# soc register map
Vendor: litex
Litex SoC 2022-08-25 21:57:28
Registers are 32-bit, read-write, reset 0x0 unless marked. A register's access mark holds for its fields unless they carry their own. Offsets are from the block's base; lines under a group give offsets from that group; [hi:lo] are bit positions; {n}, {i} and the like mark numbered series; 'fields as' and 'values as' point back to an identical list; <NAME> marks a mode.

## Memory map
0xF0000000 BPU size 0x24
0xF0000800 CTRL size 0xC
0xF0001000 DMATEST size 0x28
0xF0001800 IDENTIFIER_MEM size 0x4
0xF0002000 TIMER0 size 0x20
0xF0002800 TIMER1 size 0x20
0xF0003000 UART size 0x20

## Interrupts
0 uart (UART)
1 timer0 (TIMER0)
2 timer1 (TIMER1)
3 dmatest (DMATEST)

## Further device data
memoryRegions:
  ROM baseAddress=0x00000000 size=0x00020000
  SRAM baseAddress=0x10000000 size=0x00002000
  CSR baseAddress=0xF0000000 size=0x00010000
constants:
  CONFIG_CLOCK_FREQUENCY value=1000000
  CONFIG_CPU_HAS_INTERRUPT value=None
  CONFIG_CPU_RESET_ADDR value=0
  CONFIG_CPU_HAS_DCACHE value=None
  CONFIG_CPU_HAS_ICACHE value=None
  CONFIG_CPU_TYPE_VEXRISCV value=None
  CONFIG_CPU_VARIANT_STANDARD value=None
  CONFIG_CPU_HUMAN_NAME value=VexRiscv
  CONFIG_CPU_NOP value=nop
  CONFIG_CSR_DATA_WIDTH value=32
  CONFIG_CSR_ALIGNMENT value=32
  CONFIG_BUS_STANDARD value=WISHBONE
  CONFIG_BUS_DATA_WIDTH value=32
  CONFIG_BUS_ADDRESS_WIDTH value=32
  CONFIG_BUS_BURSTING value=0
  BPU_IDENTIFICATION value=2880249322
  DMATEST_INTERRUPT value=3
  TIMER0_INTERRUPT value=1
  TIMER1_INTERRUPT value=2
  UART_INTERRUPT value=0

## BPU
Base 0xF0000000
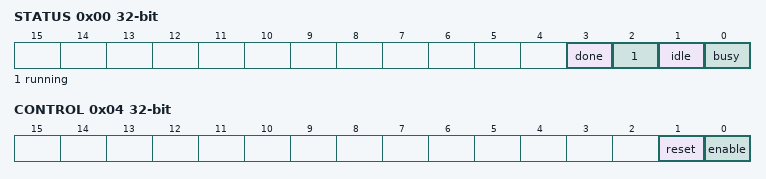
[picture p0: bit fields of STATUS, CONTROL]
0x00 STATUS — BPU Status
  [3] done — BPU Done
  [2] running — BPU Running
  [1] idle — BPU Idle
  [0] busy — BPU Busy
0x04 CONTROL
  [1] reset — Reset BPU
  [0] enable — Enable BPU
0x08 INSTRUCTION
0x0C SRC
0x10 DST
0x14 LENGTH
0x18 OFFSET
0x1C DATA
0x20 TICK

## CTRL
Base 0xF0000800
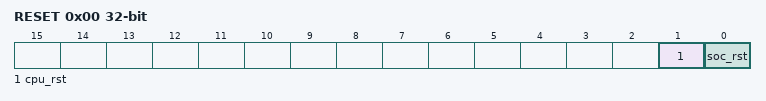
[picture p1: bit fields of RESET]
0x00 RESET
  [1] cpu_rst — Write `1` to this register to reset the CPU(s) of the SoC (Hold Reset)
  [0] soc_rst — Write `1` to this register to reset the full SoC (Pulse Reset)
0x04 SCRATCH reset 0x12345678 — Use this register as a scratch space to verify that software read/write accesses to the Wishbone/CSR bus are working correctly. The initial reset value of 0x1234578 can be used to verify endianness.
0x08 BUS_ERRORS — Total number of Wishbone bus errors (timeouts) since start.

## DMATEST
Base 0xF0001000
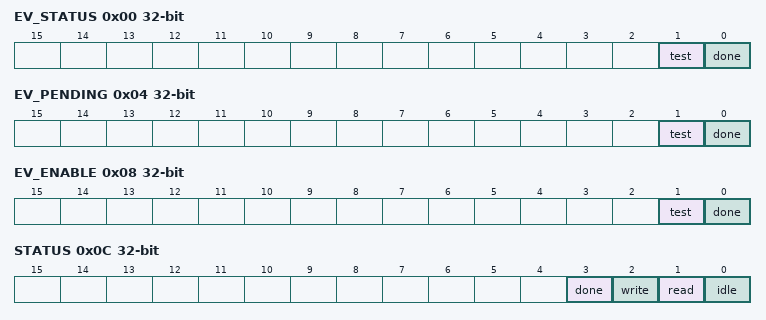
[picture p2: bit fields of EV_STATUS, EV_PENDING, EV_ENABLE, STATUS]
0x00 EV_STATUS — This register contains the current raw level of the test event trigger. Writes to this register have no effect.
  [1] test — Level of the ``test`` event
  [0] done — Level of the ``done`` event
0x04 EV_PENDING — When a test event occurs, the corresponding bit will be set in this register. To clear the Event, set the corresponding bit in this register.
  [1] test — `1` if a `test` event occurred. This Event is **level triggered** when the signal is **high**.
  [0] done — `1` if a `done` event occurred. This Event is triggered on a **falling** edge.
0x08 EV_ENABLE — This register enables the corresponding test events. Write a ``0`` to this register to disable individual events.
  [1] test — Write a ``1`` to enable the ``test`` Event
  [0] done — Write a ``1`` to enable the ``done`` Event
0x0C STATUS — DMA Status
  [3] done — DMA Done
  [2] write — DMA Write
  [1] read — DMA Read
  [0] idle — DMA Idle
0x10 CONTROL
  [0] enable — Enable DMA
0x14 SRC
0x18 DST
0x1C LENGTH
0x20 OFFSET
0x24 DATA

## IDENTIFIER_MEM
Base 0xF0001800
0x00 IDENTIFIER_MEM — 8 x 37-bit memory
  [7:0] identifier_mem

## TIMER0
Base 0xF0002000
Same registers: TIMER1 0xF0002800
0x00 LOAD — Load value when Timer is (re-)enabled. In One-Shot mode, the value written to this register specifies the Timer's duration in clock cycles.
0x04 RELOAD — Reload value when Timer reaches ``0``. In Periodic mode, the value written to this register specify the Timer's period in clock cycles.
0x08 EN — Enable flag of the Timer. Set this flag to ``1`` to enable/start the Timer. Set to ``0`` to disable the Timer.
  [0] en
0x0C UPDATE_VALUE — Update trigger for the current countdown value. A write to this register latches the current countdown value to ``value`` register.
  [0] update_value
0x10 VALUE — Latched countdown value. This value is updated by writing to ``update_value``.
0x14 EV_STATUS — This register contains the current raw level of the zero event trigger. Writes to this register have no effect.
  [0] zero — Level of the ``zero`` event
0x18 EV_PENDING — When a zero event occurs, the corresponding bit will be set in this register. To clear the Event, set the corresponding bit in this register.
  [0] zero — `1` if a `zero` event occurred. This Event is triggered on a **falling** edge.
0x1C EV_ENABLE — This register enables the corresponding zero events. Write a ``0`` to this register to disable individual events.
  [0] zero — Write a ``1`` to enable the ``zero`` Event

## UART
Base 0xF0003000
0x00 RXTX
  [7:0] rxtx
0x04 TXFULL — TX FIFO Full.
  [0] txfull
0x08 RXEMPTY — RX FIFO Empty.
  [0] rxempty
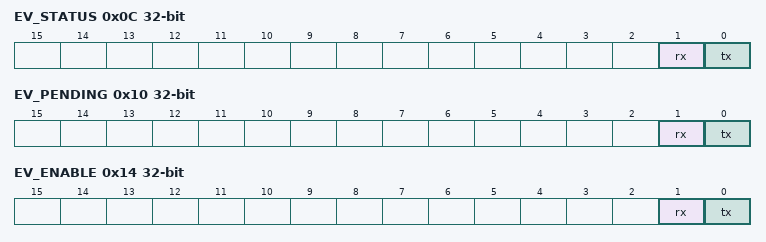
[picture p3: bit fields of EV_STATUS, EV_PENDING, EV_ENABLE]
0x0C EV_STATUS — This register contains the current raw level of the rx event trigger. Writes to this register have no effect.
  [1] rx — Level of the ``rx`` event
  [0] tx — Level of the ``tx`` event
0x10 EV_PENDING — When a rx event occurs, the corresponding bit will be set in this register. To clear the Event, set the corresponding bit in this register.
  [1] rx — `1` if a `rx` event occurred. This Event is triggered on a **falling** edge.
  [0] tx — `1` if a `tx` event occurred. This Event is triggered on a **falling** edge.
0x14 EV_ENABLE — This register enables the corresponding rx events. Write a ``0`` to this register to disable individual events.
  [1] rx — Write a ``1`` to enable the ``rx`` Event
  [0] tx — Write a ``1`` to enable the ``tx`` Event
0x18 TXEMPTY — TX FIFO Empty.
  [0] txempty
0x1C RXFULL — RX FIFO Full.
  [0] rxfull
